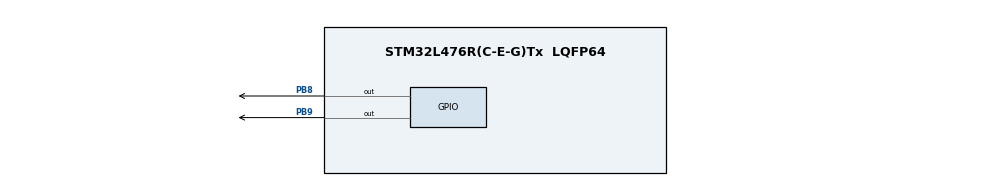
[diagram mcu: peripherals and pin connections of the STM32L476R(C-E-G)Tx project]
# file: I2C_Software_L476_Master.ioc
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Mcu.Family=STM32L4
Mcu.Name=STM32L476R(C-E-G)Tx
Mcu.Package=LQFP64
NVIC.PriorityGroup=NVIC_PRIORITYGROUP_4
PB8.GPIO_ModeDefaultOutputPP=GPIO_MODE_OUTPUT_OD
PB8.GPIO_PuPd=GPIO_PULLUP
PB8.GPIO_Speed=GPIO_SPEED_FREQ_VERY_HIGH
PB8.Signal=GPIO_Output
PB9.GPIO_ModeDefaultOutputPP=GPIO_MODE_OUTPUT_OD
PB9.GPIO_PuPd=GPIO_PULLUP
PB9.GPIO_Speed=GPIO_SPEED_FREQ_VERY_HIGH
PB9.Signal=GPIO_Output
ProjectManager.HeapSize=0x200
ProjectManager.StackSize=0x400
ProjectManager.TargetToolchain=MDK-ARM V5.32
RCC.ADCFreq_Value=16000000
RCC.AHBFreq_Value=4000000
RCC.APB1Freq_Value=4000000
RCC.APB1TimFreq_Value=4000000
RCC.APB2Freq_Value=4000000
RCC.APB2TimFreq_Value=4000000
RCC.CortexFreq_Value=4000000
RCC.HCLKFreq_Value=4000000
RCC.HSE_VALUE=8000000
RCC.HSI_VALUE=16000000
RCC.LSE_VALUE=32768
RCC.MSI_VALUE=4000000
RCC.PLLN=40
RCC.SYSCLKFreq_VALUE=4000000
RCC.USBFreq_Value=16000000
RCC.VCOOutputFreq_Value=160000000
TIM2.Period=9
TIM2.Prescaler=3
VP_TIM2_VS_ClockSourceINT.Mode=Internal
board=custom

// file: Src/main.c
/* USER CODE BEGIN Header */
/**
  ******************************************************************************
  * @file           : main.c
  * @brief          : Main program body
  ******************************************************************************
  * @attention
  *
  * Copyright (c) 2024 STMicroelectronics.
  * All rights reserved.
  *
  * This software is licensed under terms that can be found in the LICENSE file
  * in the root directory of this software component.
  * If no LICENSE file comes with this software, it is provided AS-IS.
  *
  ******************************************************************************
  */
/* USER CODE END Header */
#include "main.h"

/* USER CODE BEGIN PTD */
#define WRITE_SDA_0 	LL_GPIO_ResetOutputPin(GPIOB, LL_GPIO_PIN_9)
#define WRITE_SDA_1 	LL_GPIO_SetOutputPin(GPIOB, LL_GPIO_PIN_9)
#define WRITE_SCL_0 	LL_GPIO_ResetOutputPin(GPIOB, LL_GPIO_PIN_8)
#define WRITE_SCL_1 	LL_GPIO_SetOutputPin(GPIOB, LL_GPIO_PIN_8)
#define READ_SDA_VAL 	LL_GPIO_IsInputPinSet(GPIOB, LL_GPIO_PIN_9)

#define SLAVE_ADRESSE 0x3F
#define CMD 0x01

#define E_OK 0
#define E_NOT_OK 1
/* USER CODE END PTD */

/* USER CODE BEGIN PV */
volatile uint8_t DataTrans[] = {7, 8, 4, 2};//Data
volatile uint8_t sendCounter = 0;;
volatile uint8_t I2C_SendByteRetAddr = 0;
volatile uint8_t I2C_SendByteRetData = 0;
volatile uint32_t failedAddrCounter = 0;
/* USER CODE END PV */

void SystemClock_Config(void);
static void MX_GPIO_Init(void);
static void MX_TIM2_Init(void);
/* USER CODE BEGIN PFP */
void delay_ms(uint32_t timeDelay);
void I2C_Start(void);
void I2C_Stop(void);
uint8_t I2C_SendByte(uint8_t byte);
uint8_t I2C_ReadByte(uint8_t ack);
void I2C_Master_Init(void);
/* USER CODE END PFP */

int main(void)
{

  /* MCU Configuration--------------------------------------------------------*/

  /* Reset of all peripherals, Initializes the Flash interface and the Systick. */
  LL_APB2_GRP1_EnableClock(LL_APB2_GRP1_PERIPH_SYSCFG);
  LL_APB1_GRP1_EnableClock(LL_APB1_GRP1_PERIPH_PWR);

  /* System interrupt init*/
  NVIC_SetPriorityGrouping(NVIC_PRIORITYGROUP_4);

  /* SysTick_IRQn interrupt configuration */
  NVIC_SetPriority(SysTick_IRQn, NVIC_EncodePriority(NVIC_GetPriorityGrouping(),15, 0));

  /* Configure the system clock */
  SystemClock_Config();

  /* Initialize all configured peripherals */
  MX_GPIO_Init();
  MX_TIM2_Init();
  /* USER CODE BEGIN 2 */
	I2C_Master_Init();
  /* USER CODE END 2 */
	delay_ms(50000);
	sendCounter = 0;
	I2C_Start();
  /* Infinite loop */
  /* USER CODE BEGIN WHILE */
  while (1)
  {

		I2C_SendByteRetAddr = I2C_SendByte(SLAVE_ADRESSE << 1);
		delay_ms(1000);
    /* USER CODE END WHILE */

    /* USER CODE BEGIN 3 */
  }
	return 0;
  /* USER CODE END 3 */
}

void SystemClock_Config(void)
{
  LL_FLASH_SetLatency(LL_FLASH_LATENCY_0);
  while(LL_FLASH_GetLatency()!= LL_FLASH_LATENCY_0)
  {
  }
  LL_PWR_SetRegulVoltageScaling(LL_PWR_REGU_VOLTAGE_SCALE1);
  while (LL_PWR_IsActiveFlag_VOS() != 0)
  {
  }
  LL_RCC_MSI_Enable();

   /* Wait till MSI is ready */
  while(LL_RCC_MSI_IsReady() != 1)
  {

  }
  LL_RCC_MSI_EnableRangeSelection();
  LL_RCC_MSI_SetRange(LL_RCC_MSIRANGE_6);
  LL_RCC_MSI_SetCalibTrimming(0);
  LL_RCC_SetSysClkSource(LL_RCC_SYS_CLKSOURCE_MSI);

   /* Wait till System clock is ready */
  while(LL_RCC_GetSysClkSource() != LL_RCC_SYS_CLKSOURCE_STATUS_MSI)
  {

  }
  LL_RCC_SetAHBPrescaler(LL_RCC_SYSCLK_DIV_1);
  LL_RCC_SetAPB1Prescaler(LL_RCC_APB1_DIV_1);
  LL_RCC_SetAPB2Prescaler(LL_RCC_APB2_DIV_1);

  LL_Init1msTick(4000000);

  LL_SetSystemCoreClock(4000000);
}

static void MX_TIM2_Init(void)
{

  LL_TIM_InitTypeDef TIM_InitStruct = {0};

  /* Peripheral clock enable */
  LL_APB1_GRP1_EnableClock(LL_APB1_GRP1_PERIPH_TIM2);

  TIM_InitStruct.Prescaler = 3;
  TIM_InitStruct.CounterMode = LL_TIM_COUNTERMODE_UP;
  TIM_InitStruct.Autoreload = 9;
  TIM_InitStruct.ClockDivision = LL_TIM_CLOCKDIVISION_DIV1;
  LL_TIM_Init(TIM2, &TIM_InitStruct);
  LL_TIM_DisableARRPreload(TIM2);
  LL_TIM_SetClockSource(TIM2, LL_TIM_CLOCKSOURCE_INTERNAL);
  LL_TIM_SetTriggerOutput(TIM2, LL_TIM_TRGO_RESET);
  LL_TIM_DisableMasterSlaveMode(TIM2);
  /* USER CODE BEGIN TIM2_Init 2 */
	LL_TIM_EnableCounter(TIM2);
  /* USER CODE END TIM2_Init 2 */

}

static void MX_GPIO_Init(void)
{
  LL_GPIO_InitTypeDef GPIO_InitStruct = {0};

  /* GPIO Ports Clock Enable */
  LL_AHB2_GRP1_EnableClock(LL_AHB2_GRP1_PERIPH_GPIOB);

  /**/
  LL_GPIO_ResetOutputPin(GPIOB, LL_GPIO_PIN_8|LL_GPIO_PIN_9);

  /**/
  GPIO_InitStruct.Pin = LL_GPIO_PIN_8|LL_GPIO_PIN_9;
  GPIO_InitStruct.Mode = LL_GPIO_MODE_OUTPUT;
  GPIO_InitStruct.Speed = LL_GPIO_SPEED_FREQ_VERY_HIGH;
  GPIO_InitStruct.OutputType = LL_GPIO_OUTPUT_OPENDRAIN;
  GPIO_InitStruct.Pull = LL_GPIO_PULL_UP;
  LL_GPIO_Init(GPIOB, &GPIO_InitStruct);

}

/* USER CODE BEGIN 4 */
void delay_ms(uint32_t timeDelay)
{
    for (uint32_t i = 0; i < timeDelay; i++)
    {
        LL_TIM_SetCounter(TIM2, 0);
			  LL_TIM_EnableCounter(TIM2);
        while (!LL_TIM_IsActiveFlag_UPDATE(TIM2));
        LL_TIM_ClearFlag_UPDATE(TIM2);
    }
}

void I2C_Master_Init(void)
{
  // C?u hьnh cсc chтn SDA vр SCL ? tr?ng thсi m?c d?nh
  WRITE_SDA_1;
  WRITE_SCL_1;
}

void I2C_Start(void)
{
	WRITE_SCL_1;
	delay_ms(5);
	WRITE_SDA_1;
	delay_ms(5);
	WRITE_SDA_0;	//SDA reset to 0 before SCL.
	delay_ms(5);
	WRITE_SCL_0;
	delay_ms(5);
}

void I2C_Stop(void)
{
	WRITE_SDA_0;
	delay_ms(5);
	WRITE_SCL_1; 	//SCL set to 1 before SDA.
	delay_ms(5);
	WRITE_SDA_1;
	delay_ms(5);
}

uint8_t I2C_SendByte(uint8_t u8Data)
{
	uint8_t i;
	uint8_t stRet;
	for(int i=0; i< 8; i++)
	{		//Write byte data.
		if (u8Data & 0x80)
		{
			WRITE_SDA_1;
		}
		else
		{
			WRITE_SDA_0;
		}
		delay_ms(3);
		WRITE_SCL_1;
		delay_ms(5);
		WRITE_SCL_0;
		delay_ms(5);
		u8Data <<= 1;
	}
	WRITE_SDA_1;
	delay_ms(3);
	WRITE_SCL_1;
	delay_ms(3);

	if (READ_SDA_VAL)
	{
		stRet = E_NOT_OK;
	}
	else
	{
		stRet = E_OK;
	}

	delay_ms(2);
	WRITE_SCL_0;
	delay_ms(5);

	return stRet;
}

uint8_t I2C_ReadByte(uint8_t ack)
{
	uint8_t i;
	uint8_t u8Ret = 0x00;
	WRITE_SDA_1;
	delay_ms(3);
	for (i = 0; i < 8; ++i)
	{
		u8Ret <<= 1;
		WRITE_SCL_1;
		delay_ms(5);
		if (READ_SDA_VAL)
		{
			u8Ret |= 0x01;
		}
		delay_ms(2);
		WRITE_SCL_0;
		delay_ms(5);
	}
	if (ack)
	{
		WRITE_SDA_0;
	}
	else
	{
		WRITE_SDA_1;
	}
	delay_ms(3);
	WRITE_SCL_1;
	delay_ms(5);
	WRITE_SCL_0;
	delay_ms(5);

	return u8Ret;
}

/* USER CODE END 4 */

void Error_Handler(void)
{
  __disable_irq();
  while (1)
  {
  }
}
